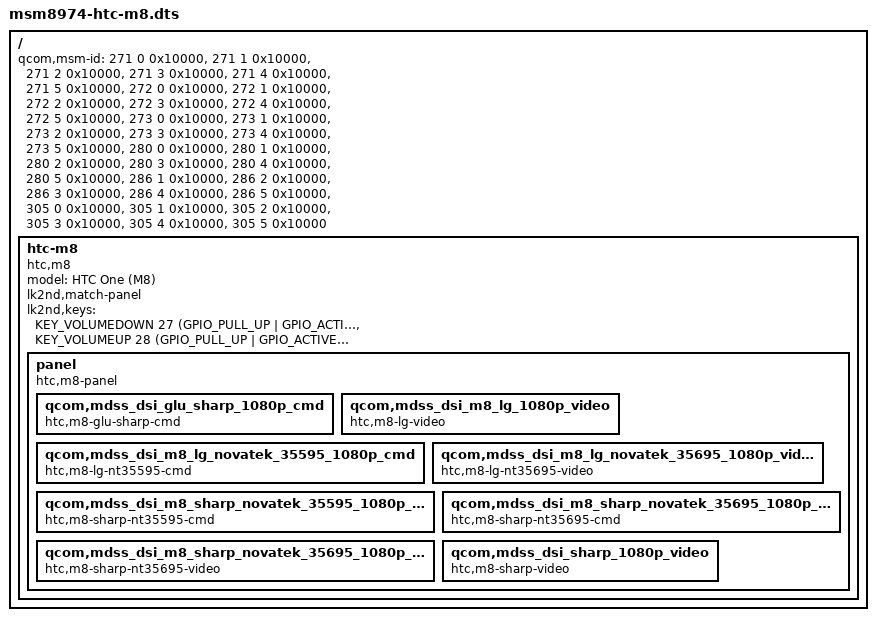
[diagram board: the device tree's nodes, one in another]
// SPDX-License-Identifier: GPL-2.0-only

/dts-v1/;

#include <skeleton.dtsi>
#include <lk2nd.h>

/ {
	/* Actually htc,project-id */
	qcom,msm-id = <271 0 0x10000>, <271 1 0x10000>, <271 2 0x10000>,
		      <271 3 0x10000>, <271 4 0x10000>, <271 5 0x10000>,
		      <272 0 0x10000>, <272 1 0x10000>, <272 2 0x10000>,
		      <272 3 0x10000>, <272 4 0x10000>, <272 5 0x10000>,
		      <273 0 0x10000>, <273 1 0x10000>, <273 2 0x10000>,
		      <273 3 0x10000>, <273 4 0x10000>, <273 5 0x10000>,
		      <280 0 0x10000>, <280 1 0x10000>, <280 2 0x10000>,
		      <280 3 0x10000>, <280 4 0x10000>, <280 5 0x10000>,
		      <286 1 0x10000>, <286 2 0x10000>, <286 3 0x10000>,
		      <286 4 0x10000>, <286 5 0x10000>,
		      <305 0 0x10000>, <305 1 0x10000>, <305 2 0x10000>,
		      <305 3 0x10000>, <305 4 0x10000>, <305 5 0x10000>;

	htc-m8 {
		model = "HTC One (M8)";
		compatible = "htc,m8", "qcom,msm8974", "lk2nd,device";
		lk2nd,match-panel;

		lk2nd,keys =
			<KEY_VOLUMEDOWN	27 (GPIO_PULL_UP | GPIO_ACTIVE_LOW)>,
			<KEY_VOLUMEUP	28 (GPIO_PULL_UP | GPIO_ACTIVE_LOW)>;

		panel {
			compatible = "htc,m8-panel";

			qcom,mdss_dsi_glu_sharp_1080p_cmd {
				compatible = "htc,m8-glu-sharp-cmd";
			};
			qcom,mdss_dsi_m8_lg_1080p_video {
				compatible = "htc,m8-lg-video";
			};
			qcom,mdss_dsi_m8_lg_novatek_35595_1080p_cmd {
				compatible = "htc,m8-lg-nt35595-cmd";
			};
			qcom,mdss_dsi_m8_lg_novatek_35695_1080p_video {
				compatible = "htc,m8-lg-nt35695-video";
			};
			qcom,mdss_dsi_m8_sharp_novatek_35595_1080p_cmd {
				compatible = "htc,m8-sharp-nt35595-cmd";
			};
			qcom,mdss_dsi_m8_sharp_novatek_35695_1080p_cmd {
				compatible = "htc,m8-sharp-nt35695-cmd";
			};
			qcom,mdss_dsi_m8_sharp_novatek_35695_1080p_video {
				compatible = "htc,m8-sharp-nt35695-video";
			};
			qcom,mdss_dsi_sharp_1080p_video {
				compatible = "htc,m8-sharp-video";
			};
		};
	};
};
